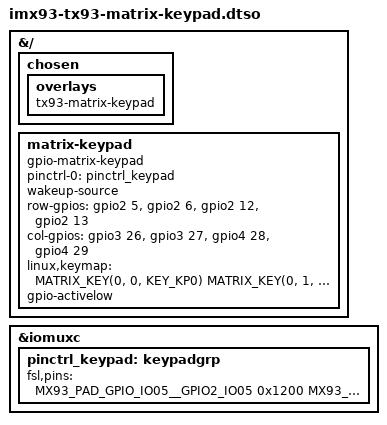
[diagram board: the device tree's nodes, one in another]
// SPDX-License-Identifier: (GPL-2.0+ OR MIT)
/*
 * Copyright 2025 Lothar Waßmann <LW@KARO-electronics.de>
 */

/dts-v1/;
/plugin/;

#include <dt-bindings/gpio/gpio.h>
#include <dt-bindings/input/input.h>
#include "imx93-pinfunc.h"

&{/} {
	chosen {
		overlays {
			tx93-matrix-keypad;
		};
	};

	matrix-keypad {
		compatible = "gpio-matrix-keypad";
		pinctrl-names = "default";
		pinctrl-0 = <&pinctrl_keypad>;
		wakeup-source;
		row-gpios = <
			     &gpio2 5 GPIO_ACTIVE_HIGH
			     &gpio2 6 GPIO_ACTIVE_HIGH
			     &gpio2 12 GPIO_ACTIVE_HIGH
			     &gpio2 13 GPIO_ACTIVE_HIGH
		>;
		col-gpios = <
			     &gpio3 26 GPIO_ACTIVE_HIGH
			     &gpio3 27 GPIO_ACTIVE_HIGH
			     &gpio4 28 GPIO_ACTIVE_HIGH
			     &gpio4 29 GPIO_ACTIVE_HIGH
		>;
		linux,keymap = <
				MATRIX_KEY(0, 0, KEY_KP0)
				MATRIX_KEY(0, 1, KEY_KP1)
				MATRIX_KEY(0, 2, KEY_KP2)
				MATRIX_KEY(0, 3, KEY_KP3)
				MATRIX_KEY(1, 0, KEY_KP4)
				MATRIX_KEY(1, 1, KEY_KP5)
				MATRIX_KEY(1, 2, KEY_KP6)
				MATRIX_KEY(1, 3, KEY_KP7)
				MATRIX_KEY(2, 0, KEY_KP8)
				MATRIX_KEY(2, 1, KEY_KP9)
				MATRIX_KEY(2, 2, KEY_ENTER)
				MATRIX_KEY(2, 3, KEY_ESC)
				MATRIX_KEY(3, 0, KEY_UP)
				MATRIX_KEY(3, 1, KEY_DOWN)
				MATRIX_KEY(3, 2, KEY_LEFT)
				MATRIX_KEY(3, 3, KEY_RIGHT)
		>;
		gpio-activelow;
	};
};

&iomuxc {
	pinctrl_keypad: keypadgrp {
		fsl,pins = <
			MX93_PAD_GPIO_IO05__GPIO2_IO05				0x1200
			MX93_PAD_GPIO_IO06__GPIO2_IO06				0x1200
			MX93_PAD_GPIO_IO12__GPIO2_IO12				0x1200
			MX93_PAD_GPIO_IO13__GPIO2_IO13				0x1200
			MX93_PAD_CCM_CLKO1__GPIO3_IO26				0x21e
			MX93_PAD_CCM_CLKO2__GPIO3_IO27				0x21e
			MX93_PAD_CCM_CLKO3__GPIO4_IO28				0x21e
			MX93_PAD_CCM_CLKO4__GPIO4_IO29				0x21e
		>;
	};
};
